# DeviceName register map
Vendor: SomeVendor; File version: 1
Device with registers of every supported size
CPU: CM3 r1p0, little endian, no MPU, no FPU, 3 interrupt priority bits
Registers are 32-bit, access not given, no defined reset value unless marked. A register's access mark holds for its fields unless they carry their own. Offsets are from the block's base; lines under a group give offsets from that group; [hi:lo] are bit positions; {n}, {i} and the like mark numbered series; 'fields as' and 'values as' point back to an identical list; <NAME> marks a mode.

## Memory map
0x40000000 PERIPH size 0x18 — Peripheral with 8, 16, 32 and 64 bit registers

## PERIPH — Peripheral with 8, 16, 32 and 64 bit registers
Base 0x40000000
0x00 CTRL — 32 bit register without fields
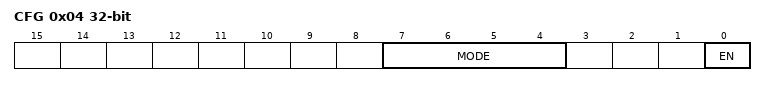
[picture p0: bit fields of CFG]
0x04 CFG — 32 bit register with fields and reserved bits
  [7:4] MODE, [0] EN
0x08 COUNT — 32 bit register with a field wider than 16 bits
  [19:0] VALUE
0x0C DATA16 16-bit — 16 bit register
0x0E DATA8 8-bit — 8 bit register
0x10 TIMESTAMP 64-bit — 64 bit register
